# PIC32MK0256GPG048 device description
Architecture: MIPS; Family: PIC32MK; Series: PIC32MK
Registers are 32-bit, read-write, no defined reset value unless marked. A register's access mark holds for its fields unless they carry their own. Offsets are from the block's base; [hi:lo] are bit positions; {n}, {i} and the like mark numbered series; 'fields as' and 'values as' point back to an identical list.

## CDAC
Instances: CDAC 0x1f82c400 in periph_pb2_std
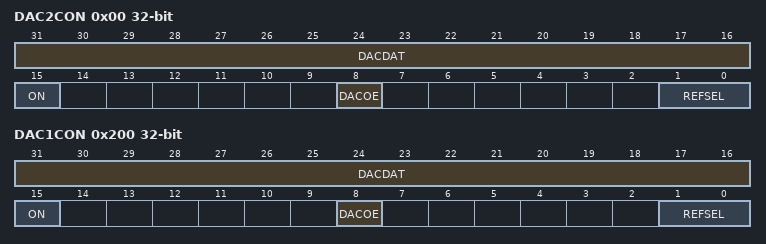
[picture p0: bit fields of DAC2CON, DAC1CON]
0x00 DAC2CON — CDAC Control Register
  [31:16] DACDAT
  [15] ON — CDAC Enable bit
    1=The CDAC is enabled; 0=The CDAC is disabled
  [8] DACOE — CDAC Output Buffer Enable bit
    1=Output is enabled; CDAC voltage is connected to the pin; 0=Output is disabled; drive to pin is floating
  [1:0] REFSEL — Reference Source Select bits
    3=Positive reference voltage = AVDD; 0=No reference selected (no reference current consumption)
0x200 DAC1CON — CDAC Control Register
  fields as DAC2CON

## CFG
Instances: CFG 0x1f800000 in periph_pb1_std
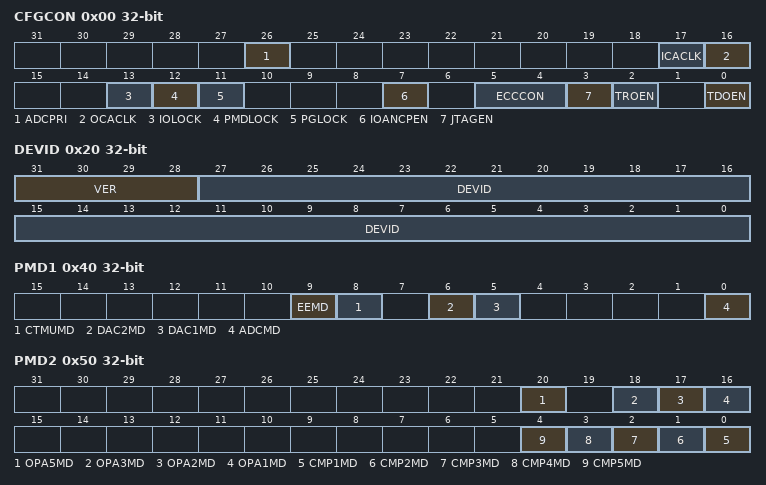
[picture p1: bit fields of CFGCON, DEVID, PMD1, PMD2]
0x00 CFGCON — Configuration Control Register
  [26] ADCPRI — ADC Arbitration Priority to SRAM bit
    1=ADC gets High Priority access to SRAM; 0=ADC uses Least Recently Serviced Arbitration (same as other initiators)
  [17] ICACLK — Input Capture Alternate Clock Selection bit
    1=Input Capture modules use an alternative Timer pair as their timebase clock; 0=All Input Capture modules use Timer2/3 as their timebase clock
  [16] OCACLK — Output Compare Alternate Clock Selection bit
    1=Output Compare modules use an alternative Timer pair as their timebase clock; 0=All Output Compare modules use Timer2/3 as their timebase clock
  [13] IOLOCK — Peripheral Pin Select Lock bit
    1=Peripheral Pin Select is locked. Writes to PPS registers are not allowed; 0=Peripheral Pin Select is not locked. Writes to PPS registers are allowed
  [12] PMDLOCK — Peripheral Module Disable bit
    1=Peripheral module is locked. Writes to PMD registers are not allowed; 0=Peripheral module is not locked. Writes to PMD registers are allowed
  [11] PGLOCK — Permission Group Lock bit
    1=Permission Group registers are locked. Writes to PG registers are not allowed; 0=Permission Group registers are not locked. Writes to PG registers are allowed
  [7] IOANCPEN — I/O Analog Charge Pump Enable bit
    1=Charge pump is enabled; 0=Charge pump is disabled (default)
  [5:4] ECCCON — Flash ECC Configuration bits
    3=ECC and dynamic ECC are disabled (ECCCON bits are writable); 2=ECC and dynamic ECC are disabled (ECCCON bits are locked); 1=Dynamic Flash ECC is enabled (ECCCON bits are locked); 0=Flash ECC is enabled (ECCCON bits are locked; disables word Flash writes)
  [3] JTAGEN — JTAG Port Enable bit
    1=Enable the JTAG port; 0=Disable the JTAG port
  [2] TROEN — Trace Output Enable bit
    1=Enable trace outputs and start trace clock (trace probe must be present); 0=Disable trace outputs and stop trace clock
  [0] TDOEN — TDO Enable for 2-Wire JTAG
    1=2-wire JTAG protocol uses TDO; 0=2-wire JTAG protocol does not use TDO
0x20 DEVID
  [31:28] VER, [27:0] DEVID
0x30 SYSKEY
0x40 PMD1
  [9] EEMD, [8] CTMUMD, [6] DAC2MD, [5] DAC1MD, [0] ADCMD
0x50 PMD2
  [20] OPA5MD, [18] OPA3MD, [17] OPA2MD, [16] OPA1MD, [n-1] CMP{n}MD (n=1..5)
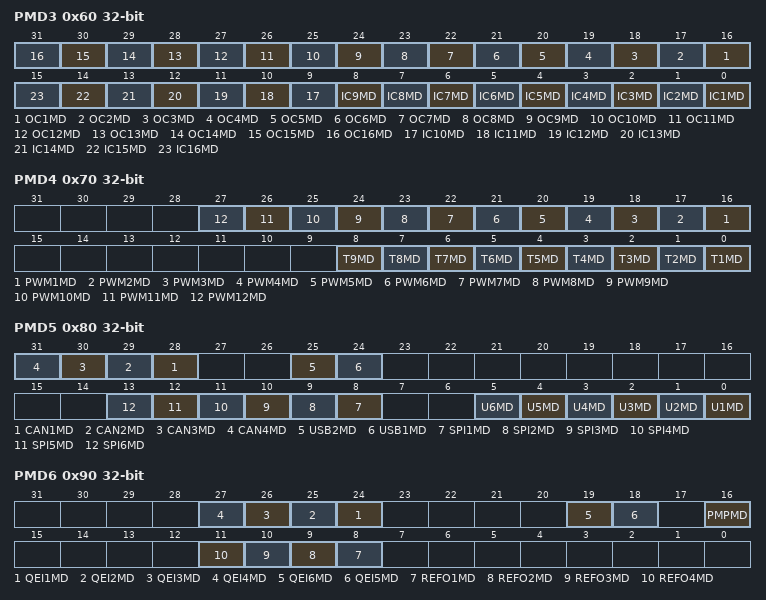
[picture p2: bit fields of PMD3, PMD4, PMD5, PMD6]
0x60 PMD3
  [n+15] OC{n}MD (n=1..16), [n-1] IC{n}MD (n=1..16)
0x70 PMD4
  [n+15] PWM{n}MD (n=1..12), [n-1] T{n}MD (n=1..9)
0x80 PMD5
  [n+27] CAN{n}MD (n=1..4), [25] USB2MD, [24] USB1MD, [n+7] SPI{n}MD (n=1..6), [n-1] U{n}MD (n=1..6)
0x90 PMD6
  [n+23] QEI{n}MD (n=1..4), [19] QEI6MD, [18] QEI5MD, [16] PMPMD, [n+7] REFO{n}MD (n=1..4)
0xA0 PMD7
  [4] DMAMD
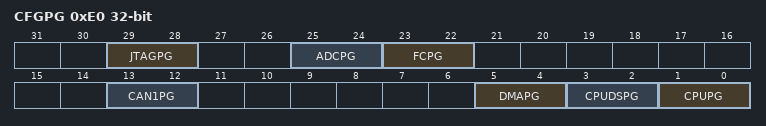
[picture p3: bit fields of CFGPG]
0xE0 CFGPG — Permission Group Configuration Register
  [all] fields
    {v}=(If RDPER({v}) is 1) read access / (If WRPER({v}) is 1) write access (v=0..3)
  [29:28] JTAGPG — JTAG Permission Group bits
  [25:24] ADCPG — ADC Permission bits
  [23:22] FCPG — Flash Control Permission Group bits
  [13:12] CAN1PG — CAN1 Module Permission Group bits
  [5:4] DMAPG — DMA Module Permission Group bits
  [3:2] CPUDSPG — CPU Instruction Data Space Permission Group bits
  [1:0] CPUPG — CPU Instruction Space Permission Group bits
0xF0 CFGAPP2
  [21] POSCFAIL — Primary Oscillator Unable to Lock Status Read-only bit
    0=Crystal or Resonator usage failed; 0=Crystal or resonator is locked or is indeterminate. If successfully locked, clock status is determined bythe SPLLRDY (CLKSTAT(7)) status flag.
0x100 CFGCON2
  [7:0] EEWS

## Notices in the file
Copyright (c) 2019 Microchip Technology Inc.
SPDX-License-Identifier: Apache-2.0
Licensed under the Apache License, Version 2.0 (the "License");
you may not use this file except in compliance with the License.
You may obtain a copy of the License at
http://www.apache.org/licenses/LICENSE-2.0
Unless required by applicable law or agreed to in writing, software
distributed under the License is distributed on an "AS IS" BASIS,
WITHOUT WARRANTIES OR CONDITIONS OF ANY KIND, either express or implied.
See the License for the specific language governing permissions and
limitations under the License.
